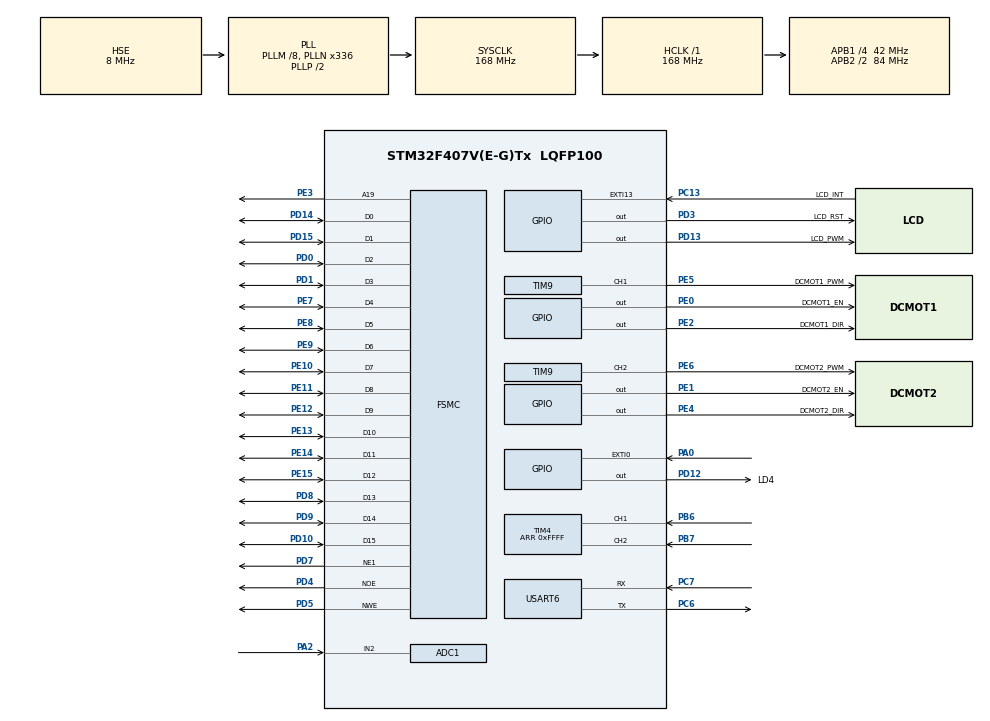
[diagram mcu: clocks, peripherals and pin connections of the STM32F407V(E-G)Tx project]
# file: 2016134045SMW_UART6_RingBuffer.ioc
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ADC1.Channel-0\#ChannelRegularConversion=ADC_CHANNEL_2
ADC1.NbrOfConversionFlag=1
ADC1.Rank-0\#ChannelRegularConversion=1
ADC1.SamplingTime-0\#ChannelRegularConversion=ADC_SAMPLETIME_3CYCLES
ADC1.master=1
FSMC.AddressSetupTime1=0
FSMC.BusTurnAroundDuration1=0
FSMC.DataSetupTime1=9
FSMC.ExtendedAddressSetupTime1=1
FSMC.ExtendedBusTurnAroundDuration1=1
FSMC.ExtendedDataSetupTime1=10
FSMC.ExtendedMode1=FSMC_EXTENDED_MODE_ENABLE
Mcu.Family=STM32F4
Mcu.Name=STM32F407V(E-G)Tx
Mcu.Package=LQFP100
NVIC.EXTI0_IRQn=true\:0\:0\:false\:false\:true\:true
NVIC.PriorityGroup=NVIC_PRIORITYGROUP_4
NVIC.TIM3_IRQn=true\:0\:0\:false\:true\:true\:2\:true
NVIC.USART6_IRQn=true\:0\:0\:false\:true\:true\:1\:true
PA0-WKUP.Signal=GPXTI0
PA13.Mode=Serial_Wire
PA13.Signal=SYS_JTMS-SWDIO
PA14.Mode=Serial_Wire
PA14.Signal=SYS_JTCK-SWCLK
PA2.Signal=ADCx_IN2
PB6.Signal=S_TIM4_CH1
PB7.Signal=S_TIM4_CH2
PC13-ANTI_TAMP.GPIO_Label=LCD_INT
PC13-ANTI_TAMP.Signal=GPXTI13
PC14-OSC32_IN.Mode=LSE-External-Oscillator
PC14-OSC32_IN.Signal=RCC_OSC32_IN
PC15-OSC32_OUT.Mode=LSE-External-Oscillator
PC15-OSC32_OUT.Signal=RCC_OSC32_OUT
PC6.Mode=Asynchronous
PC6.Signal=USART6_TX
PC7.Mode=Asynchronous
PC7.Signal=USART6_RX
PD0.Mode=16b-d1
PD0.Signal=FSMC_D2
PD1.Mode=16b-d1
PD1.Signal=FSMC_D3
PD10.Mode=16b-d1
PD10.Signal=FSMC_D15
PD12.GPIO_Label=LD4
PD12.GPIO_Speed=GPIO_SPEED_FREQ_VERY_HIGH
PD12.Signal=GPIO_Output
PD13.GPIO_Label=LCD_PWM
PD13.GPIO_Speed=GPIO_SPEED_FREQ_MEDIUM
PD13.PinState=GPIO_PIN_SET
PD13.Signal=GPIO_Output
PD14.Mode=16b-d1
PD14.Signal=FSMC_D0
PD15.Mode=16b-d1
PD15.Signal=FSMC_D1
PD3.GPIO_Label=LCD_RST
PD3.GPIO_Speed=GPIO_SPEED_FREQ_VERY_HIGH
PD3.Signal=GPIO_Output
PD4.Mode=Lcd1
PD4.Signal=FSMC_NOE
PD5.Mode=Lcd1
PD5.Signal=FSMC_NWE
PD7.Mode=NorPsramChipSelect1_1
PD7.Signal=FSMC_NE1
PD8.Mode=16b-d1
PD8.Signal=FSMC_D13
PD9.Mode=16b-d1
PD9.Signal=FSMC_D14
PE0.GPIO_Label=DCMOT1_EN
PE0.Signal=GPIO_Output
PE1.GPIO_Label=DCMOT2_EN
PE1.GPIO_Speed=GPIO_SPEED_FREQ_VERY_HIGH
PE1.Signal=GPIO_Output
PE10.Mode=16b-d1
PE10.Signal=FSMC_D7
PE11.Mode=16b-d1
PE11.Signal=FSMC_D8
PE12.Mode=16b-d1
PE12.Signal=FSMC_D9
PE13.Mode=16b-d1
PE13.Signal=FSMC_D10
PE14.Mode=16b-d1
PE14.Signal=FSMC_D11
PE15.Mode=16b-d1
PE15.Signal=FSMC_D12
PE2.GPIO_Label=DCMOT1_DIR
PE2.GPIO_Speed=GPIO_SPEED_FREQ_VERY_HIGH
PE2.Signal=GPIO_Output
PE3.Mode=A19_1
PE3.Signal=FSMC_A19
PE4.GPIO_Label=DCMOT2_DIR
PE4.GPIO_Speed=GPIO_SPEED_FREQ_VERY_HIGH
PE4.Signal=GPIO_Output
PE5.GPIO_Label=DCMOT1_PWM
PE5.GPIO_Speed=GPIO_SPEED_FREQ_VERY_HIGH
PE5.Signal=S_TIM9_CH1
PE6.GPIO_Label=DCMOT2_PWM
PE6.GPIO_Speed=GPIO_SPEED_FREQ_VERY_HIGH
PE6.Signal=S_TIM9_CH2
PE7.Mode=16b-d1
PE7.Signal=FSMC_D4
PE8.Mode=16b-d1
PE8.Signal=FSMC_D5
PE9.Mode=16b-d1
PE9.Signal=FSMC_D6
PH0-OSC_IN.Mode=HSE-External-Oscillator
PH0-OSC_IN.Signal=RCC_OSC_IN
PH1-OSC_OUT.Mode=HSE-External-Oscillator
PH1-OSC_OUT.Signal=RCC_OSC_OUT
ProjectManager.HeapSize=0x200
ProjectManager.StackSize=0x400
ProjectManager.TargetToolchain=EWARM V8
RCC.48MHZClocksFreq_Value=84000000
RCC.AHBFreq_Value=168000000
RCC.APB1CLKDivider=RCC_HCLK_DIV4
RCC.APB1Freq_Value=42000000
RCC.APB1TimFreq_Value=84000000
RCC.APB2CLKDivider=RCC_HCLK_DIV2
RCC.APB2Freq_Value=84000000
RCC.APB2TimFreq_Value=168000000
RCC.CortexFreq_Value=168000000
RCC.HCLKFreq_Value=168000000
RCC.HSE_VALUE=8000000
RCC.HSI_VALUE=16000000
RCC.PLLM=8
RCC.PLLN=336
RCC.PLLSourceVirtual=RCC_PLLSOURCE_HSE
RCC.SYSCLKFreq_VALUE=168000000
RCC.SYSCLKSource=RCC_SYSCLKSOURCE_PLLCLK
RCC.VCOOutputFreq_Value=336000000
SH.ADCx_IN2.0=ADC1_IN2,IN2
SH.S_TIM4_CH1.0=TIM4_CH1,Encoder_Interface
SH.S_TIM4_CH2.0=TIM4_CH2,Encoder_Interface
SH.S_TIM9_CH1.0=TIM9_CH1,PWM Generation1 CH1
SH.S_TIM9_CH2.0=TIM9_CH2,PWM Generation2 CH2
TIM3.Period=1000-1
TIM3.Prescaler=84-1
TIM4.Period=0xFFFF
TIM9.Channel-PWM\ Generation1\ CH1=TIM_CHANNEL_1
TIM9.Channel-PWM\ Generation2\ CH2=TIM_CHANNEL_2
TIM9.Period=100-1
TIM9.Prescaler=84-1
TIM9.Pulse-PWM\ Generation1\ CH1=0
TIM9.Pulse-PWM\ Generation2\ CH2=0
USART6.VirtualMode=VM_ASYNC
VP_TIM3_VS_ClockSourceINT.Mode=Internal
VP_TIM9_VS_ClockSourceINT.Mode=Internal
board=custom

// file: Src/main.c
/* USER CODE BEGIN Header */
/**
  ******************************************************************************
  * @file           : main.c
  * @brief          : Main program body
  ******************************************************************************
  ** This notice applies to any and all portions of this file
  * that are not between comment pairs USER CODE BEGIN and
  * USER CODE END. Other portions of this file, whether
  * inserted by the user or by software development tools
  * are owned by their respective copyright owners.
  *
  * COPYRIGHT(c) 2019 STMicroelectronics
  *
  * Redistribution and use in source and binary forms, with or without modification,
  * are permitted provided that the following conditions are met:
  *   1. Redistributions of source code must retain the above copyright notice,
  *      this list of conditions and the following disclaimer.
  *   2. Redistributions in binary form must reproduce the above copyright notice,
  *      this list of conditions and the following disclaimer in the documentation
  *      and/or other materials provided with the distribution.
  *   3. Neither the name of STMicroelectronics nor the names of its contributors
  *      may be used to endorse or promote products derived from this software
  *      without specific prior written permission.
  *
  * THIS SOFTWARE IS PROVIDED BY THE COPYRIGHT HOLDERS AND CONTRIBUTORS "AS IS"
  * AND ANY EXPRESS OR IMPLIED WARRANTIES, INCLUDING, BUT NOT LIMITED TO, THE
  * IMPLIED WARRANTIES OF MERCHANTABILITY AND FITNESS FOR A PARTICULAR PURPOSE ARE
  * DISCLAIMED. IN NO EVENT SHALL THE COPYRIGHT HOLDER OR CONTRIBUTORS BE LIABLE
  * FOR ANY DIRECT, INDIRECT, INCIDENTAL, SPECIAL, EXEMPLARY, OR CONSEQUENTIAL
  * DAMAGES (INCLUDING, BUT NOT LIMITED TO, PROCUREMENT OF SUBSTITUTE GOODS OR
  * SERVICES; LOSS OF USE, DATA, OR PROFITS; OR BUSINESS INTERRUPTION) HOWEVER
  * CAUSED AND ON ANY THEORY OF LIABILITY, WHETHER IN CONTRACT, STRICT LIABILITY,
  * OR TORT (INCLUDING NEGLIGENCE OR OTHERWISE) ARISING IN ANY WAY OUT OF THE USE
  * OF THIS SOFTWARE, EVEN IF ADVISED OF THE POSSIBILITY OF SUCH DAMAGE.
  *
  ******************************************************************************
  */
/* USER CODE END Header */

#include "main.h"

/* USER CODE BEGIN Includes */
#include <stdio.h>
#include <string.h>
#include <stdlib.h>
#include <ctype.h>

#include <string.h>
#include <math.h>

#include "stm32f4_discovery_lcd.h"

#include "circular-byte-buffer.h"

#include "DcMotor.h"
#include "DcMotorExtern.h"

#include "mathext.h"

#include "Packet.h"
#include "PacketExtern.h"
/* USER CODE END Includes */

ADC_HandleTypeDef hadc1;

TIM_HandleTypeDef htim3;
TIM_HandleTypeDef htim4;
TIM_HandleTypeDef htim9;

UART_HandleTypeDef huart6;

SRAM_HandleTypeDef hsram1;

/* USER CODE BEGIN PV */
//100 글자 링버퍼 생성
CIRC_BBUF_DEF(CircleBuffer, 100);
//수신된 패킷
typePacket PacketRx;

int8_t rx;

typedef enum _bool{
  FALSE = 0,
  TRUE =1
} bool;

struct{
  float Kp;
  float Ki;
  float Kd;
} PidParam={0.0 , 0.0 , 0.0};// UART통신을 통해 값 입력

//PidParam={0.3, 0.002, 0.005}; // PID 보정 값
enum {
  STATE_IDLE = 0,
  STATE_RUN_SAVE,
  STATE_NORUN_PRINT,
  STATE_RUN_ONLY,
} RunState={STATE_IDLE};  // 초기값 STATE_IDLE

bool flagTim3=FALSE;
int16_t flagUser=0; //user button press

/* USER CODE END PV */

void SystemClock_Config(void);
static void MX_GPIO_Init(void);
static void MX_FSMC_Init(void);
static void MX_USART6_UART_Init(void);
static void MX_ADC1_Init(void);
static void MX_TIM3_Init(void);
static void MX_TIM9_Init(void);
static void MX_TIM4_Init(void);
static void MX_NVIC_Init(void);

/* USER CODE BEGIN 0 */
char strReceive1[30]="P1.123034";
char strReceive2[30]="I2.345001";
char strReceive3[30]="D6.67890";
char strReceive4[30]="E10000";
char strReceive5[30]="K10.3 5.7 9";

typeController PidController1;

int flagUart=0;

#define LCD_X0 10
#define LCD_Y0 215
#define LCD_GRAPH_WIDTH  300
#define LCD_GRAPH_HEIGHT 200

void LCD_Plot_Axis(void)
{
  //  STM32f4_Discovery_LCD_Init();
  STM32f4_HAL_Discovery_LCD_Init();

  /* Display message on stm32f4_discovery LCD **********************************/
  /* Clear the LCD */
  LCD_Clear(LCD_COLOR_BLACK);

  /* Set the LCD Back Color */
  LCD_SetBackColor(LCD_COLOR_BLACK);
  /* Set the LCD Text Color */
  LCD_SetTextColor(LCD_COLOR_WHITE);

 //300x200으로 사각형 그리기
  LCD_DrawRect(LCD_X0-1, LCD_Y0-(LCD_GRAPH_HEIGHT+1),
               LCD_X0+(LCD_GRAPH_WIDTH+1), LCD_Y0-15 );
  LCD_DrawLine(LCD_X0-1, LCD_Y0, LCD_GRAPH_WIDTH+1, LCD_DIR_HORIZONTAL);

  LCD_SetTextColor(LCD_COLOR_BLUE);
  LCD_DrawLine(LCD_X0+1, LCD_Y0-150, LCD_GRAPH_WIDTH+2, LCD_DIR_HORIZONTAL);
  LCD_SetTextColor(LCD_COLOR_WHITE);

   LCD_SetFont(&LCD_DEFAULT_FONT);
}

void PidControlInit()
{
  // DC Motor 관련변수 초기화
    DcMotor1.Encoder16Old = 0;
    DcMotor1.Encoder32 = 0;
    DcMotor1.Encoder32Old = 0;
    DcMotor1.Encoder32Diff = 0;

   // 제어기 관련변수 초기화
    Controller1.Target32 = WHEEL_RESOLUTION;
    Controller1.ErrorOld32 = 0;
    Controller1.ErrorSum32 =0;
    Controller1.loop =0;

    //PWM duty =0
    DcMotor1SetDutyPulse(&htim9, 0);
    DcMotor2SetDutyPulse(&htim9, 0);

    //htim4->CNT <= 0x0000 (16bit 카운터)
    __HAL_TIM_SET_COUNTER(&htim4,   0x0000);
}

void PidControl()
{
   float TermKp,TermKi,TermKd;
   Controller1.Error32 = Controller1.Target32- Controller1.Output32; // 목표값과 현재 플랜트 출력의 오차
   Controller1.ErrorSum32 += Controller1.Error32; //오차의 합(적분값)
   Controller1.ErrorDiff32 = Controller1.Error32- Controller1.ErrorOld32; // 샘플간 오차의 차이(미분값)
   Controller1.ErrorOld32 = Controller1.Error32;

   //ErrorSum 최대값 제한
   #define ERRROR_SUM_MAX  (WHEEL_RESOLUTION*100)
 //  Controller1.ErrorSum = LimitFloat(Controller1.ErrorSum , ERRROR_SUM_MAX);
   #undef ERRROR_SUM_MAX

    TermKp =  PidParam.Kp * Controller1.Error32 ; //비례제어값
    TermKi = PidParam.Ki * Controller1.ErrorSum32 * Tsample; //적분제어값
    TermKd =  PidParam.Kd * Controller1.ErrorDiff32 / Tsample ;//미분제어값
    Controller1.f = TermKp + TermKi + TermKd;

    //PWM pulse 실수=>정수값 변환
    Controller1.U = FloatToInt16Limit( Controller1.f ,  U_MAX);
    //PWM dead zone 피하기
    Controller1.U  = AvoidDeadzone(Controller1.U, 14, -14);
    //PWM pulse 값 설정
    DcMotor1SetDutyPulse(&htim9, Controller1.U);

}

void PidControlRecord()
{
    Backup1.RecordOutput[Controller1.loop]= Controller1.Output32;
    Backup1.RecordU[Controller1.loop] = Controller1.U;
//    DcMotor1.Recordu[DcMotor1.loop] = DcMotor1.u;
//    DcMotor1.RecordError[DcMotor1.loop] = DcMotor1.Error;
//   DcMotor1.RecordErrorSum[DcMotor1.loop] = DcMotor1.ErrorSum;
//   DcMotor1.RecordErrorDiff[DcMotor1.loop] = DcMotor1.ErrorDiff;
}

void PidControlResultTransmit()
{
  char string[200];
  HAL_UART_Transmit(&huart6, (uint8_t *)"Record Print\r\n", strlen("Record Print\r\n"), 1000);
  for(int i=0 ; i<RECORD_MAX ; i++ ){
      sprintf(string, "%7d %5d %6d \r\n", i, Backup1.RecordOutput[i], Backup1.RecordU[i]);
      HAL_UART_Transmit( &huart6, (uint8_t *)string, strlen(string), 1000);
  }
}

uint16_t Y1[300];

void Plot()
{
   char string[200];
   uint16_t y, x;
   x= Controller1.loop %300 ;
   LCD_SetTextColor(LCD_COLOR_BLACK);
   y=(int32_t)( Y1[Controller1.loop]/(float)Controller1.Target32*150.0+0.5);
   LCD_PutPixel(LCD_X0+x, LCD_Y0-y);

   Y1[Controller1.loop] = Controller1.Output32;
   LCD_SetTextColor(LCD_COLOR_WHITE);
   //목표값을 y축의 150선상에 놓기
   y=(int32_t)( Y1[Controller1.loop]/(float)Controller1.Target32*150.0+0.5);
   LCD_PutPixel(LCD_X0+x, LCD_Y0-y);

   sprintf(string, "%6d", Controller1.Output32);
   LCD_DisplayStringLine(LCD_LINE_0, (uint8_t *)string);

}

#ifdef __GNUC__
   #define PUTCHAR_PROTOTYPE int __io_putchar(int ch)
#else
   #define PUTCHAR_PROTOTYPE int fputc(int ch, FILE *f)
#endif
PUTCHAR_PROTOTYPE
{
   HAL_UART_Transmit(&huart6, (uint8_t *)&ch, 1, 1);
   return ch;
}

/* USER CODE END 0 */

int main(void)
{
  /* USER CODE BEGIN 1 */
 char string[200];
 PidParam.Kp=0.0;
  /* USER CODE END 1 */

  /* MCU Configuration--------------------------------------------------------*/

  /* Reset of all peripherals, Initializes the Flash interface and the Systick. */
  HAL_Init();

  /* Configure the system clock */
  SystemClock_Config();

  /* Initialize all configured peripherals */
  MX_GPIO_Init();
  MX_FSMC_Init();
  MX_USART6_UART_Init();
  MX_ADC1_Init();
  MX_TIM3_Init();
  MX_TIM9_Init();
  MX_TIM4_Init();

  /* Initialize interrupts */
  MX_NVIC_Init();
  /* USER CODE BEGIN 2 */
HAL_UART_Receive_IT(&huart6, (uint8_t *)&rx, 1);

  LCD_Plot_Axis();//LCD에 그래프 박스 그리기

  HAL_UART_Transmit(&huart6, (uint8_t *)"Start\r\n", strlen("Start\r\n"), 1000);

  //TIM9 PWM outpout 시작
  HAL_TIM_PWM_Start(&htim9, TIM_CHANNEL_1);
  HAL_TIM_PWM_Start(&htim9, TIM_CHANNEL_2);
  //TIM4 encoder mode 시작
  HAL_TIM_Encoder_Start(&htim4, TIM_CHANNEL_1 | TIM_CHANNEL_2);
  //TIM3  time interrupt 시작
  HAL_TIM_Base_Start_IT(&htim3);

  //Pid제어기 초기화
  PidControlInit();
  /* USER CODE END 2 */

  /* Infinite loop */
  while (1)
  {

    /* USER CODE BEGIN 3 */
              //수신패킷수가 1개 이상 있으면
         if(  countPacket > 0){
           //링버퍼에서 패킷 추출
           PacketExtractFromBuffer( &CircleBuffer, &PacketRx);
           //추출된 패킷 분석
           PacketParsing(&PacketRx);
         }
          if( flagTim3==TRUE){
            //LD4에 오실로스코우프 프로브 연결 파형 측정
            HAL_GPIO_WritePin(LD4_GPIO_Port, LD4_Pin,GPIO_PIN_SET);

            switch(RunState){
               case STATE_RUN_SAVE:
                 if(Controller1.loop< RECORD_MAX){
                     PidControl();                              //PID 제어
                     PidControlRecord();                    //그 전 값 기록
                     Plot();                                     //GLCD를 통한 그래프
                     Controller1.loop++;
                  }else {
                     Controller1.loop = 0;
                   //  RunState = STATE_RUN_ONLY;
                  }
                  printf("Kp= %10.3f %10.3f %10.3f \r\n", PidParam.Kp, PidParam.Ki, PidParam.Kd);// main문에서의 재 확인 동작
                  HAL_Delay(300);
                  RunState = STATE_RUN_ONLY;// 0.3초 후 Run_Only 모드 전환
                  break;

               case STATE_NORUN_PRINT:
                  //TIM3 interrupt disable
                  HAL_NVIC_DisableIRQ( TIM3_IRQn);
                  PidControlResultTransmit();
                  Controller1.loop = 0;
                 // RunState = STATE_RUN_ONLY;  // 수작업 을 통해 바뀜
                  //TIM3 interrupt enable
                  HAL_NVIC_EnableIRQ( TIM3_IRQn);
                  break;

               case STATE_RUN_ONLY:
                  HAL_TIM_PWM_Start(&htim9, TIM_CHANNEL_1);
                  HAL_TIM_PWM_Start(&htim9, TIM_CHANNEL_2);
                   //TIM4 encoder mode 시작
                  HAL_TIM_Encoder_Start(&htim4, TIM_CHANNEL_1 | TIM_CHANNEL_2);
                 PidControl();                                                        // PID 제어
                  sprintf(string, " %6d", Controller1.Output32);              //엔코더 값을 문자열로 변경
                  LCD_DisplayStringLine(LCD_LINE_0, (uint8_t *)string);   //LCD에 출력
                  break;

            case STATE_IDLE:                                        //초기화
                HAL_TIM_PWM_Stop(&htim9, TIM_CHANNEL_1);
                HAL_TIM_PWM_Stop(&htim9, TIM_CHANNEL_2);
                //TIM4 encoder mode  끝
                HAL_TIM_Encoder_Stop(&htim4, TIM_CHANNEL_1 | TIM_CHANNEL_2);
              break;
            }

            flagTim3=FALSE;
            HAL_GPIO_WritePin(LD4_GPIO_Port, LD4_Pin,GPIO_PIN_RESET);
        }
  }
  /* USER CODE END 3 */
}

void SystemClock_Config(void)
{
  RCC_OscInitTypeDef RCC_OscInitStruct = {0};
  RCC_ClkInitTypeDef RCC_ClkInitStruct = {0};

  /**Configure the main internal regulator output voltage
  */
  __HAL_RCC_PWR_CLK_ENABLE();
  __HAL_PWR_VOLTAGESCALING_CONFIG(PWR_REGULATOR_VOLTAGE_SCALE1);
  /**Initializes the CPU, AHB and APB busses clocks
  */
  RCC_OscInitStruct.OscillatorType = RCC_OSCILLATORTYPE_HSE;
  RCC_OscInitStruct.HSEState = RCC_HSE_ON;
  RCC_OscInitStruct.PLL.PLLState = RCC_PLL_ON;
  RCC_OscInitStruct.PLL.PLLSource = RCC_PLLSOURCE_HSE;
  RCC_OscInitStruct.PLL.PLLM = 8;
  RCC_OscInitStruct.PLL.PLLN = 336;
  RCC_OscInitStruct.PLL.PLLP = RCC_PLLP_DIV2;
  RCC_OscInitStruct.PLL.PLLQ = 4;
  if (HAL_RCC_OscConfig(&RCC_OscInitStruct) != HAL_OK)
  {
    Error_Handler();
  }
  /**Initializes the CPU, AHB and APB busses clocks
  */
  RCC_ClkInitStruct.ClockType = RCC_CLOCKTYPE_HCLK|RCC_CLOCKTYPE_SYSCLK
                              |RCC_CLOCKTYPE_PCLK1|RCC_CLOCKTYPE_PCLK2;
  RCC_ClkInitStruct.SYSCLKSource = RCC_SYSCLKSOURCE_PLLCLK;
  RCC_ClkInitStruct.AHBCLKDivider = RCC_SYSCLK_DIV1;
  RCC_ClkInitStruct.APB1CLKDivider = RCC_HCLK_DIV4;
  RCC_ClkInitStruct.APB2CLKDivider = RCC_HCLK_DIV2;

  if (HAL_RCC_ClockConfig(&RCC_ClkInitStruct, FLASH_LATENCY_5) != HAL_OK)
  {
    Error_Handler();
  }
}

/**
  * @brief NVIC Configuration.
  * @retval None
  */
static void MX_NVIC_Init(void)
{
  /* USART6_IRQn interrupt configuration */
  HAL_NVIC_SetPriority(USART6_IRQn, 0, 0);
  HAL_NVIC_EnableIRQ(USART6_IRQn);
  /* TIM3_IRQn interrupt configuration */
  HAL_NVIC_SetPriority(TIM3_IRQn, 0, 0);
  HAL_NVIC_EnableIRQ(TIM3_IRQn);
}

static void MX_ADC1_Init(void)
{

  ADC_ChannelConfTypeDef sConfig = {0};

  /**Configure the global features of the ADC (Clock, Resolution, Data Alignment and number of conversion)
  */
  hadc1.Instance = ADC1;
  hadc1.Init.ClockPrescaler = ADC_CLOCK_SYNC_PCLK_DIV4;
  hadc1.Init.Resolution = ADC_RESOLUTION_12B;
  hadc1.Init.ScanConvMode = DISABLE;
  hadc1.Init.ContinuousConvMode = DISABLE;
  hadc1.Init.DiscontinuousConvMode = DISABLE;
  hadc1.Init.ExternalTrigConvEdge = ADC_EXTERNALTRIGCONVEDGE_NONE;
  hadc1.Init.ExternalTrigConv = ADC_SOFTWARE_START;
  hadc1.Init.DataAlign = ADC_DATAALIGN_RIGHT;
  hadc1.Init.NbrOfConversion = 1;
  hadc1.Init.DMAContinuousRequests = DISABLE;
  hadc1.Init.EOCSelection = ADC_EOC_SINGLE_CONV;
  if (HAL_ADC_Init(&hadc1) != HAL_OK)
  {
    Error_Handler();
  }
  /**Configure for the selected ADC regular channel its corresponding rank in the sequencer and its sample time.
  */
  sConfig.Channel = ADC_CHANNEL_2;
  sConfig.Rank = 1;
  sConfig.SamplingTime = ADC_SAMPLETIME_3CYCLES;
  if (HAL_ADC_ConfigChannel(&hadc1, &sConfig) != HAL_OK)
  {
    Error_Handler();
  }

}

static void MX_TIM3_Init(void)
{

  TIM_ClockConfigTypeDef sClockSourceConfig = {0};
  TIM_MasterConfigTypeDef sMasterConfig = {0};

  htim3.Instance = TIM3;
  htim3.Init.Prescaler = 84-1;
  htim3.Init.CounterMode = TIM_COUNTERMODE_UP;
  htim3.Init.Period = 1000-1;
  htim3.Init.ClockDivision = TIM_CLOCKDIVISION_DIV1;
  if (HAL_TIM_Base_Init(&htim3) != HAL_OK)
  {
    Error_Handler();
  }
  sClockSourceConfig.ClockSource = TIM_CLOCKSOURCE_INTERNAL;
  if (HAL_TIM_ConfigClockSource(&htim3, &sClockSourceConfig) != HAL_OK)
  {
    Error_Handler();
  }
  sMasterConfig.MasterOutputTrigger = TIM_TRGO_RESET;
  sMasterConfig.MasterSlaveMode = TIM_MASTERSLAVEMODE_DISABLE;
  if (HAL_TIMEx_MasterConfigSynchronization(&htim3, &sMasterConfig) != HAL_OK)
  {
    Error_Handler();
  }

}

static void MX_TIM4_Init(void)
{

  TIM_Encoder_InitTypeDef sConfig = {0};
  TIM_MasterConfigTypeDef sMasterConfig = {0};

  htim4.Instance = TIM4;
  htim4.Init.Prescaler = 0;
  htim4.Init.CounterMode = TIM_COUNTERMODE_UP;
  htim4.Init.Period = 0xFFFF;
  htim4.Init.ClockDivision = TIM_CLOCKDIVISION_DIV1;
  sConfig.EncoderMode = TIM_ENCODERMODE_TI1;
  sConfig.IC1Polarity = TIM_ICPOLARITY_RISING;
  sConfig.IC1Selection = TIM_ICSELECTION_DIRECTTI;
  sConfig.IC1Prescaler = TIM_ICPSC_DIV1;
  sConfig.IC1Filter = 0;
  sConfig.IC2Polarity = TIM_ICPOLARITY_RISING;
  sConfig.IC2Selection = TIM_ICSELECTION_DIRECTTI;
  sConfig.IC2Prescaler = TIM_ICPSC_DIV1;
  sConfig.IC2Filter = 0;
  if (HAL_TIM_Encoder_Init(&htim4, &sConfig) != HAL_OK)
  {
    Error_Handler();
  }
  sMasterConfig.MasterOutputTrigger = TIM_TRGO_RESET;
  sMasterConfig.MasterSlaveMode = TIM_MASTERSLAVEMODE_DISABLE;
  if (HAL_TIMEx_MasterConfigSynchronization(&htim4, &sMasterConfig) != HAL_OK)
  {
    Error_Handler();
  }

}

static void MX_TIM9_Init(void)
{

  TIM_ClockConfigTypeDef sClockSourceConfig = {0};
  TIM_OC_InitTypeDef sConfigOC = {0};

  htim9.Instance = TIM9;
  htim9.Init.Prescaler = 84-1;
  htim9.Init.CounterMode = TIM_COUNTERMODE_UP;
  htim9.Init.Period = 100-1;
  htim9.Init.ClockDivision = TIM_CLOCKDIVISION_DIV1;
  if (HAL_TIM_Base_Init(&htim9) != HAL_OK)
  {
    Error_Handler();
  }
  sClockSourceConfig.ClockSource = TIM_CLOCKSOURCE_INTERNAL;
  if (HAL_TIM_ConfigClockSource(&htim9, &sClockSourceConfig) != HAL_OK)
  {
    Error_Handler();
  }
  if (HAL_TIM_PWM_Init(&htim9) != HAL_OK)
  {
    Error_Handler();
  }
  sConfigOC.OCMode = TIM_OCMODE_PWM1;
  sConfigOC.Pulse = 0;
  sConfigOC.OCPolarity = TIM_OCPOLARITY_HIGH;
  sConfigOC.OCFastMode = TIM_OCFAST_DISABLE;
  if (HAL_TIM_PWM_ConfigChannel(&htim9, &sConfigOC, TIM_CHANNEL_1) != HAL_OK)
  {
    Error_Handler();
  }
  if (HAL_TIM_PWM_ConfigChannel(&htim9, &sConfigOC, TIM_CHANNEL_2) != HAL_OK)
  {
    Error_Handler();
  }
  HAL_TIM_MspPostInit(&htim9);

}

static void MX_USART6_UART_Init(void)
{

  huart6.Instance = USART6;
  huart6.Init.BaudRate = 115200;
  huart6.Init.WordLength = UART_WORDLENGTH_8B;
  huart6.Init.StopBits = UART_STOPBITS_1;
  huart6.Init.Parity = UART_PARITY_NONE;
  huart6.Init.Mode = UART_MODE_TX_RX;
  huart6.Init.HwFlowCtl = UART_HWCONTROL_NONE;
  huart6.Init.OverSampling = UART_OVERSAMPLING_16;
  if (HAL_UART_Init(&huart6) != HAL_OK)
  {
    Error_Handler();
  }

}

static void MX_GPIO_Init(void)
{
  GPIO_InitTypeDef GPIO_InitStruct = {0};

  /* GPIO Ports Clock Enable */
  __HAL_RCC_GPIOE_CLK_ENABLE();
  __HAL_RCC_GPIOC_CLK_ENABLE();
  __HAL_RCC_GPIOH_CLK_ENABLE();
  __HAL_RCC_GPIOA_CLK_ENABLE();
  __HAL_RCC_GPIOD_CLK_ENABLE();
  __HAL_RCC_GPIOB_CLK_ENABLE();

  /*Configure GPIO pin Output Level */
  HAL_GPIO_WritePin(GPIOE, DCMOT1_DIR_Pin|DCMOT2_DIR_Pin|DCMOT1_EN_Pin|DCMOT2_EN_Pin, GPIO_PIN_RESET);

  /*Configure GPIO pin Output Level */
  HAL_GPIO_WritePin(GPIOD, LD4_Pin|LD3_Pin|LCD_RST_Pin, GPIO_PIN_RESET);
  /*Configure GPIO pin Output Level */
  HAL_GPIO_WritePin(LCD_PWM_GPIO_Port, LCD_PWM_Pin, GPIO_PIN_SET);

  /*Configure GPIO pins : DCMOT1_DIR_Pin DCMOT2_DIR_Pin DCMOT2_EN_Pin */
  GPIO_InitStruct.Pin = DCMOT1_DIR_Pin|DCMOT2_DIR_Pin|DCMOT2_EN_Pin;
  GPIO_InitStruct.Mode = GPIO_MODE_OUTPUT_PP;
  GPIO_InitStruct.Pull = GPIO_NOPULL;
  GPIO_InitStruct.Speed = GPIO_SPEED_FREQ_VERY_HIGH;
  HAL_GPIO_Init(GPIOE, &GPIO_InitStruct);

  /*Configure GPIO pin : LCD_INT_Pin */
  GPIO_InitStruct.Pin = LCD_INT_Pin;
  GPIO_InitStruct.Mode = GPIO_MODE_IT_RISING;
  GPIO_InitStruct.Pull = GPIO_NOPULL;
  HAL_GPIO_Init(LCD_INT_GPIO_Port, &GPIO_InitStruct);

  /*Configure GPIO pin : PA0 */
  GPIO_InitStruct.Pin = GPIO_PIN_0;
  GPIO_InitStruct.Mode = GPIO_MODE_IT_RISING;
  GPIO_InitStruct.Pull = GPIO_NOPULL;
  HAL_GPIO_Init(GPIOA, &GPIO_InitStruct);

  /*Configure GPIO pins : LD4_Pin LCD_RST_Pin */
  GPIO_InitStruct.Pin = LD4_Pin|LD3_Pin|LCD_RST_Pin;
  GPIO_InitStruct.Mode = GPIO_MODE_OUTPUT_PP;
  GPIO_InitStruct.Pull = GPIO_NOPULL;
  GPIO_InitStruct.Speed = GPIO_SPEED_FREQ_VERY_HIGH;
  HAL_GPIO_Init(GPIOD, &GPIO_InitStruct);

  /*Configure GPIO pin : LCD_PWM_Pin */
  GPIO_InitStruct.Pin = LCD_PWM_Pin;
  GPIO_InitStruct.Mode = GPIO_MODE_OUTPUT_PP;
  GPIO_InitStruct.Pull = GPIO_NOPULL;
  GPIO_InitStruct.Speed = GPIO_SPEED_FREQ_MEDIUM;
  HAL_GPIO_Init(LCD_PWM_GPIO_Port, &GPIO_InitStruct);

  /*Configure GPIO pin : DCMOT1_EN_Pin */
  GPIO_InitStruct.Pin = DCMOT1_EN_Pin;
  GPIO_InitStruct.Mode = GPIO_MODE_OUTPUT_PP;
  GPIO_InitStruct.Pull = GPIO_NOPULL;
  GPIO_InitStruct.Speed = GPIO_SPEED_FREQ_LOW;
  HAL_GPIO_Init(DCMOT1_EN_GPIO_Port, &GPIO_InitStruct);

  /* EXTI interrupt init*/
  HAL_NVIC_SetPriority(EXTI0_IRQn, 0, 0);
  HAL_NVIC_EnableIRQ(EXTI0_IRQn);

}

/* FSMC initialization function */
static void MX_FSMC_Init(void)
{
  FSMC_NORSRAM_TimingTypeDef Timing;
  FSMC_NORSRAM_TimingTypeDef ExtTiming;

  /** Perform the SRAM1 memory initialization sequence
  */
  hsram1.Instance = FSMC_NORSRAM_DEVICE;
  hsram1.Extended = FSMC_NORSRAM_EXTENDED_DEVICE;
  /* hsram1.Init */
  hsram1.Init.NSBank = FSMC_NORSRAM_BANK1;
  hsram1.Init.DataAddressMux = FSMC_DATA_ADDRESS_MUX_DISABLE;
  hsram1.Init.MemoryType = FSMC_MEMORY_TYPE_SRAM;
  hsram1.Init.MemoryDataWidth = FSMC_NORSRAM_MEM_BUS_WIDTH_16;
  hsram1.Init.BurstAccessMode = FSMC_BURST_ACCESS_MODE_DISABLE;
  hsram1.Init.WaitSignalPolarity = FSMC_WAIT_SIGNAL_POLARITY_LOW;
  hsram1.Init.WrapMode = FSMC_WRAP_MODE_DISABLE;
  hsram1.Init.WaitSignalActive = FSMC_WAIT_TIMING_BEFORE_WS;
  hsram1.Init.WriteOperation = FSMC_WRITE_OPERATION_ENABLE;
  hsram1.Init.WaitSignal = FSMC_WAIT_SIGNAL_DISABLE;
  hsram1.Init.ExtendedMode = FSMC_EXTENDED_MODE_ENABLE;
  hsram1.Init.AsynchronousWait = FSMC_ASYNCHRONOUS_WAIT_DISABLE;
  hsram1.Init.WriteBurst = FSMC_WRITE_BURST_DISABLE;
  hsram1.Init.PageSize = FSMC_PAGE_SIZE_NONE;
  /* Timing */
  Timing.AddressSetupTime = 0;
  Timing.AddressHoldTime = 15;
  Timing.DataSetupTime = 9;
  Timing.BusTurnAroundDuration = 0;
  Timing.CLKDivision = 16;
  Timing.DataLatency = 17;
  Timing.AccessMode = FSMC_ACCESS_MODE_A;
  /* ExtTiming */
  ExtTiming.AddressSetupTime = 1;
  ExtTiming.AddressHoldTime = 15;
  ExtTiming.DataSetupTime = 10;
  ExtTiming.BusTurnAroundDuration = 1;
  ExtTiming.CLKDivision = 16;
  ExtTiming.DataLatency = 17;
  ExtTiming.AccessMode = FSMC_ACCESS_MODE_A;

  if (HAL_SRAM_Init(&hsram1, &Timing, &ExtTiming) != HAL_OK)
  {
    Error_Handler( );
  }

}

/* USER CODE BEGIN 4 */
void HAL_GPIO_EXTI_Callback(uint16_t GPIO_Pin)
{
  if(GPIO_Pin== GPIO_PIN_0){
    flagUser =1;
  }
}

void HAL_TIM_PeriodElapsedCallback(TIM_HandleTypeDef *htim)
{
   if( htim->Instance == TIM3) {
      flagTim3 = TRUE;

      //엔코더 위치 및 샘플링당 엔코더차이(속도) 16bit 계산
      DcMotor1.Encoder16 = DcMotor1ReadEncoder();
      DcMotor1.Encoder16Diff= DcMotor1.Encoder16- DcMotor1.Encoder16Old;
      DcMotor1.Encoder16Old = DcMotor1.Encoder16;

       //엔코더 위치 및 샘플링당 엔코더차이(속도) 32bit 로 확장
      DcMotor1.Encoder32 += DcMotor1.Encoder16Diff;
      DcMotor1.Encoder32Diff = DcMotor1.Encoder32- DcMotor1.Encoder32Old;
      DcMotor1.Encoder32Old = DcMotor1.Encoder32;

      Controller1.Output32 = DcMotor1.Encoder32;
   }
}
void HAL_UART_TxCpltCallback(UART_HandleTypeDef *huart)
{
}

void HAL_UART_RxCpltCallback(UART_HandleTypeDef *huart)
{
  if (huart->Instance == USART6)
  {
      if ( circ_bbuf_free_space(&CircleBuffer) ==0) CircleBuffer.full =1;
       else {
            if (rx != PACKET_END ) //수신문자열끝(CR=\r) 확인, 보통은 링버퍼에 삽입
               circ_bbuf_push(&CircleBuffer, rx);
            else{ //수신문자열끝인 (CR=\r)오면 문자열 처리 편리을 위해 NULL로 변경하여 삽입
              circ_bbuf_push(&CircleBuffer, ASCII_NUL);
              //수신패킷수를 증가
              countPacket ++;
            }
       }
       /*
       if (rx =='K' |'k'){
       RunState = STATE_RUN_SAVE;  //
        HAL_GPIO_WritePin(LD3_GPIO_Port, LD3_Pin,GPIO_PIN_SET);

       }
       else if (rx =='I' |'i'){
       RunState = STATE_RUN_ONLY;
        HAL_GPIO_WritePin(LD3_GPIO_Port, LD3_Pin,GPIO_PIN_RESET);

       }
        */
       HAL_UART_Receive_IT(&huart6, (uint8_t *)&rx, 1);
      flagUart =1;
  }
}
/* USER CODE END 4 */

void Error_Handler(void)
{
}

/************************ (C) COPYRIGHT STMicroelectronics *****END OF FILE****/
